# SN32F290 register map
Vendor: SONIX; File version: 2026.10.03
CPU: CM0 r0p0, little endian, no MPU, no FPU, 2 interrupt priority bits
Registers are 32-bit, read-write, reset 0x0 unless marked. A register's access mark holds for its fields unless they carry their own. Offsets are from the block's base; [hi:lo] are bit positions.

## SN_UART0 — UART0
Base 0x40016000
Same registers: SN_UART3 0x40052000, SN_UART2 0x40054000, SN_UART1 0x40056000
0x00 DLL (alternate view of RB) — Offset:0x00 UARTn Divisor Latch LSB Register
  [7:0] DLL — DLL and DLM register determines the baud rate of UARTn
0x00 RB ro — Offset:0x00 UARTn Receiver Buffer Register
  [7:0] RB — The received byte in UART RX FIFO
0x00 TH wo (alternate view of RB) — Offset:0x00 UARTn Transmit Holding Register
  [7:0] TH — The byte to be transmitted in UART TX FIFO when transmitter is available
0x04 DLM — Offset:0x04 UARTn Divisor Latch MSB Register
  [7:0] DLM — DLL and DLM register determines the baud rate of USARTn
0x04 IE (reset mask 0x317) (alternate view of DLM) — Offset:0x04 UARTn Interrupt Enable Register
  [18:9] ABTOIE — ABT0 interrupt enable
    0=Disable_434 (Disable ABTO interrupt); 1=Enable_145 (Enable ABTO interrupt)
  [16:8] ABEOIE — ABE0 interrupt enable
    0=Disable_434 (Disable ABEO interrupt); 1=Enable_145 (Enable ABEO interrupt)
  [8:4] TEMTIE — TEMT interrupt enable
    0=Disable_434 (Disable TEMT interrupt); 1=Enable_145 (Enable TEMT interrupt)
  [4:2] RLSIE — RLS interrupt enable
    0=Disable_434 (Disable RLS interrupt); 1=Enable_145 (Enable RLS interrupt)
  [2:1] THREIE — THRE interrupt enable
    0=Disable_434 (Disable THRE interrupt); 1=Enable_145 (Enable THRE interrupt)
  [0] RDAIE — RDA interrupt enable
    0=Disable_434 (Disable RDA interrupt); 1=Enable_145 (Enable RDA interrupt)
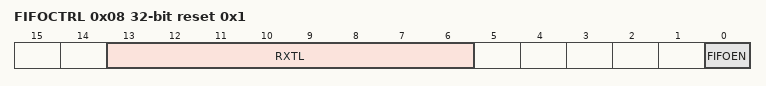
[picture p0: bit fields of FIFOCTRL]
0x08 FIFOCTRL wo reset 0x1 (reset mask 0xC1) — Offset:0x08 UARTn FIFO Control Register
  [13:6] RXTL — RX trigger level
    0=Trigger_level_0 (1 character)
  [0] FIFOEN — FIFO enable
    0=No_effect_200; 1=Enable_145 (Enable FIFO)
0x08 II ro reset 0x41 (reset mask 0x3CF) — Offset:0x08 UARTn Interrupt Identification Register
  [18:9] ABTOIF — ABTO interrupt flag
    0=Not_Time_out_2 (Auto-baud has not timed out); 1=Time_out_3 (Auto-baud has timed out and interrupt is enabled)
  [16:8] ABEOIF — ABEO interrupt flag
    0=Not_end_3 (Auto-baud has not finished); 1=End_4 (Auto-baud has finished and interrupt is enabled)
  [13:6] FIFOEN — Equal to FIFOEN bits in USARTn_FIFOCTRL register
  [4:1] INTID — Interrupt ID of RX FIFO
    1=V_3a_4 (THRE interrupt); 2=V_2a_2 (RDA (Receive Data Available)); 3=V_1_374 (RLS (Receive Line Status)); 7=V_3b (TEMT interrupt)
  [0] INTSTATUS — Interrupt status
    0=Pending_3 (As least 1 interrupt is pending); 1=No_interrupt_21
0x0C LC (reset mask 0xFF) — Offset:0x0C UARTn Line Control Register
  [14:7] DLAB — Divisor Latch access
    0=Disable_434 (Disable access to Divisor Latch); 1=Enable_145 (Enable access to Divisor Latch)
  [12:6] BC — Break control
    0=Disable_434 (Disable break transmission); 1=Enable_145 (Enable break transmission)
  [9:4] PS — Parity selection
    0=V_0_164 (Odd parity); 1=V_1_374 (Even parity); 2=V_2 (Forced 1 sticky parity); 3=V_3_20 (Forced 0 sticky parity)
  [6:3] PE — Parity enable
    0=Disable_434 (Disable parity generation and checking); 1=Enable_145 (Enable parity generation and checking)
  [4:2] SBS — Stop bit selection
    0=V_1_stop_bit_4 (1 stop bit); 1=V_2_stop_bit (2 stop bit (1.5 stop bit if WLS=0))
  [1:0] WLS — Word length selection
    0=V_5_bit_4 (5-bit character); 1=V_6_bit_3 (6-bit character); 2=V_7_bit_4 (7-bit character); 3=V_8_bit_5 (8-bit character)
0x14 LS ro reset 0x60 (reset mask 0xFF) — Offset:0x14 UARTn Line Status Register
  [14:7] RXFE — Receiver FIFO error flag
    0=No_RX_FIFO_error (UARTn_RB contains no UART RX errors); 1=RX_FIFO_error (UARTn_RB contains at least 1 UART RX error)
  [12:6] TEMT — Transmitter empty flag
    0=Not_empty (THR and/or TSR contains valid data); 1=Empty_4 (THR and TSR are both empty)
  [10:5] THRE — THR empty flag
    0=Not_empty (THR contains valid data); 1=Empty_4 (THR (TX FIFO) is empty)
  [8:4] BI — Break interrupt flag
    0=No_58 (No break interrupt); 1=Break interrupt status is active
  [6:3] FE — Framing error flag
    0=No_58 (No framing error); 1=Framing_error_3 (Framing error status is active)
  [4:2] PE — Parity error flag
    0=No_58 (No parity error); 1=Parity_error_4 (Parity error status is active)
  [2:1] OE — Overrun error flag
    0=No_58 (No overrun error); 1=Overrun_error_2 (Overrun error status is active)
  [0] RDR — Receiver data ready flag
    0=Not_ready_2 (UARTn_RB FIFO is empty); 1=Ready_8 (UARTn_RB FIFO contains valid data)
0x1C SP — Offset:0x1C UARTn Scratch Pad Register
  [7:0] PAD — Pad informaton
0x20 ABCTRL (reset mask 0x307) — Offset:0x20 UARTn Auto-baud Control Register
  [18:9] ABTOIFC wo — Clear ABTOIF flag
    0=No_effect_200; 1=Clear_V_150 (Clear ABTOIF bit)
  [16:8] ABEOIFC wo — Clear ABEOIF flag
    0=No_effect_200; 1=Clear_V_150 (Clear ABEOIF bit)
  [4:2] AUTORESTART — Restart mode selection
    0=No_restart; 1=Restart_3 (Auto restart in case of timeout)
  [2:1] MODE — Auto-baud mode selection
    0=Mode_0_2 (Auto-baud mode 0); 1=Mode_1_2 (Auto-baud mode 1)
  [0] START — Auto-baud run bit
    0=Stop_5 (Auto-baud is not running); 1=Auto-baud ids running
0x28 FD (reset mask 0x1FF) — Offset:0x28 UARTn Fractional Divider Register
  [16:8] OVER8 — Oversampling value
    0=V_16_8 (Oversampling by 16); 1=V_8_2 (Oversampling by 8)
  [11:4] MULVAL — Baud rate generation prescaler multiplier value
    0=V_0000_4 (Baud rate prescaler multiplier value is 1); 1=V_0001_3 (Baud rate prescaler multiplier value is 2); 10=V_1010_2 (Baud rate prescaler multiplier value is 11); 11=V_1011_2 (Baud rate prescaler multiplier value is 12); 12=V_1100_6 (Baud rate prescaler multiplier value is 13); 13=V_1101_3 (Baud rate prescaler multiplier value is 14); 14=V_1110_5 (Baud rate prescaler multiplier value is 15); 15=V_1111 (Baud rate prescaler multiplier value is 16); 2=V_0010_2 (Baud rate prescaler multiplier value is 3); 3=V_0011_4 (Baud rate prescaler multiplier value is 4); 4=V_0100_6 (Baud rate prescaler multiplier value is 5); 5=V_0101_4 (Baud rate prescaler multiplier value is 6); 6=V_0110 (Baud rate prescaler multiplier value is 7); 7=V_0111_5 (Baud rate prescaler multiplier value is 8); 8=V_1000_3 (Baud rate prescaler multiplier value is 9); 9=V_1001_3 (Baud rate prescaler multiplier value is 10)
  [3:0] DIVADDVAL — Baud rate generation prescaler divisor value
0x30 CTRL reset 0xC0 (reset mask 0xCF) — Offset:0x30 UARTn Control Register
  [14:7] TXEN — TX enable
    0=Disable_434 (Disable TX); 1=Enable_145 (Enable TX)
  [12:6] RXEN — RX enable
    0=Disable_434 (Disable RX); 1=Enable_145 (Enable RX)
  [4:1] MODE — UART mode
    0=V_0_164 (UART mode)
  [0] UARTEN — USART enable
    0=Disable_434 (Disable UART); 1=Enable_145 (Enable UART)
0x34 HDEN — Offset:0x34 UARTn Control Register
  [0] HDEN — Half-duplex mode enable
    0=Disable_434 (Disable half-duplex mode); 1=Enable_145 (Enable half-duplex mode)
